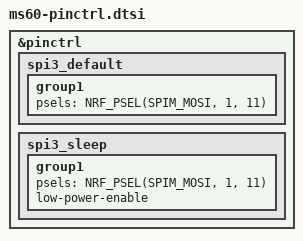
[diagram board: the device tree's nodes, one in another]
&pinctrl {

spi3_default: spi3_default {
        group1 {
            psels = <NRF_PSEL(SPIM_MOSI, 1, 11)>;
        };
    };

    spi3_sleep: spi3_sleep {
        group1 {
            psels = <NRF_PSEL(SPIM_MOSI, 1, 11)>;
            low-power-enable;
        };
    };
};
